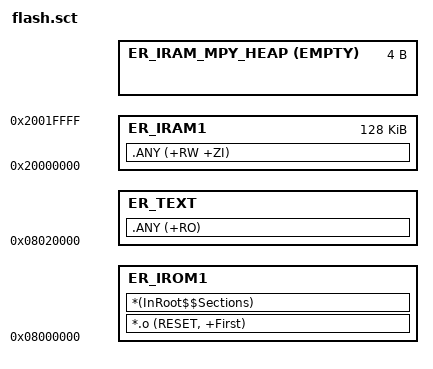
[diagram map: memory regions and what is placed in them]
; *************************************************************
; *** Scatter-Loading Description File generated by uVision ***
; *************************************************************

LR_IROM1 0x08000000 16*1024  {    ; load region size_region
  ER_IROM1 +0  {  ; load address = execution address
   *.o (RESET, +First)
   *(InRoot$$Sections)
  }
 }

LR_IROM2 0x08020000 384*1024  {
  ER_TEXT +0 {
	.ANY (+RO)  
  }
  
  ER_IRAM1 0x20000000 128*1024  {  ; RW data
   .ANY (+RW +ZI)
  }
  ER_IRAM_MPY_HEAP +0 EMPTY 4 {
  }
}

